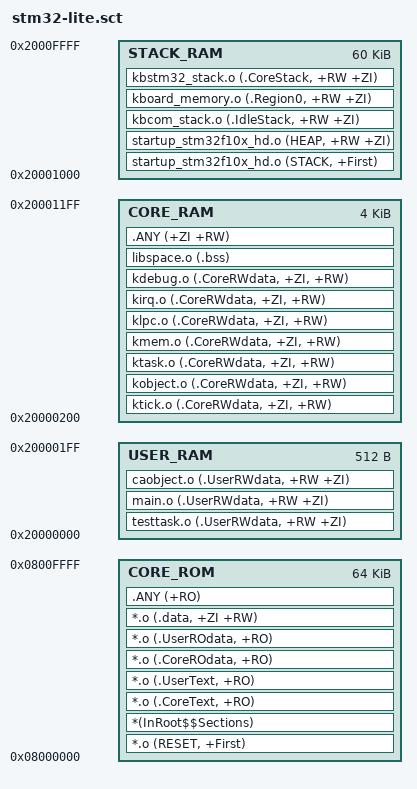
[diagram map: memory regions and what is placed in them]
;
;    This is open source software.
;    Learning and research can be unrestricted to  modification, use and dissemination.
;    If you need for commercial purposes, you should get the author's permission.
;
;    Configuration:
;     System global core stack                  NO
;     The local core stack of general task      YES
;     The loacl core stack of kernel task       YES
;     The local user stack of general task      NO
;     Hardware supported task switch IRQ        YES
;     Hardware supported double stack           NO
;
;    date           author          notes
;    2015-06-25     JiangYong       new file

LR_IROM1 0x08000000 0x00010000  {    ; load region size_region
  CORE_ROM 0x08000000 0x00010000  {  ; load address = execution address
   *.o (RESET, +First)
   *(InRoot$$Sections)
   *.o (.CoreText, +RO)
   *.o (.UserText, +RO)
   *.o (.CoreROdata, +RO)
   *.o (.UserROdata, +RO)
   *.o (.data, +ZI +RW)
   .ANY (+RO)
  }

  USER_RAM 0x20000000 0x00000200  {  ; RW data
   testtask.o (.UserRWdata, +RW +ZI)
   main.o (.UserRWdata, +RW +ZI)
   caobject.o (.UserRWdata, +RW +ZI)
  }

  CORE_RAM 0x20000200 0x00001000  {  ; RW data
   ktick.o (.CoreRWdata, +ZI, +RW)
   kobject.o (.CoreRWdata, +ZI, +RW)
   ktask.o (.CoreRWdata, +ZI, +RW)
   kmem.o (.CoreRWdata, +ZI, +RW)
   klpc.o (.CoreRWdata, +ZI, +RW)
   kirq.o (.CoreRWdata, +ZI, +RW)
   kdebug.o (.CoreRWdata, +ZI, +RW)
   libspace.o (.bss)
   .ANY (+ZI +RW)
  }

  STACK_RAM 0x20001000 0x0000f000  {  ; RW data
   startup_stm32f10x_hd.o (STACK, +First)
   startup_stm32f10x_hd.o (HEAP, +RW +ZI)
   kbcom_stack.o (.IdleStack, +RW +ZI)
   kboard_memory.o (.Region0, +RW +ZI)
   kbstm32_stack.o (.CoreStack, +RW +ZI)
  }
}

